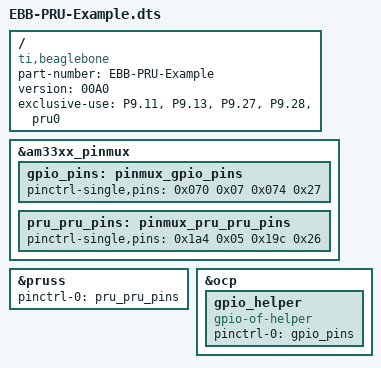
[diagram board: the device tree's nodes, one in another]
/dts-v1/;
/plugin/;

/ {
	compatible = "ti,beaglebone", "ti,beaglebone-black";
	part-number = "EBB-PRU-Example";
	version = "00A0";
	
	/* This overlay uses the following resources */
	exclusive-use = "P9.11", "P9.13", "P9.27", "P9.28", "pru0";

	fragment@0 {
		target = <&am33xx_pinmux>;
		__overlay__ {
		
			gpio_pins: pinmux_gpio_pins {  //The GPIO pins
				pinctrl-single,pins = <
					0x070 0x07 // P9_11 MODE7 // GPIO output pull-down
					0x074 0x27 // P9_13 MODE7 // GPIO input pull-down Wrong mode???
			
					/* OUTPUT  GPIO(mode7) 0x07 pulldown, 0x17 pullup, 0x?f no pullup/down */
					/* INPUT   GPIO(mode7) 0x27 pulldown, 0x37 pullup, 0x?f no pullup/down */
				>;
			};

			pru_pru_pins: pinmux_pru_pru_pins { //The PRU pin modes
				pinctrl-single,pins = <
					0x1a4 0x05 // P9_27 pr1_pru0_pru_r30_5, Mode5 output pull-down
					0x19c 0x26 // P9_28 pr1_pru0_pru_r31_3, Mode6 input pull-down
				>;
			};
		};
	};

	fragment@1 { // Enable the PRUSS
		target = <&pruss>;
		__overlay__ {
			status = "okay";
			pinctrl-names = "default";
			pinctrl-0 = <&pru_pru_pins>;
        };
    };
    
	fragment@2 { // Enable the GPIOs
		target = <&ocp>;
		__overlay__ {
			gpio_helper {
				compatible = "gpio-of-helper";
				status = "okay";
				pinctrl-names = "default";
				pinctrl-0 = <&gpio_pins>;
            };
        };
    };
};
